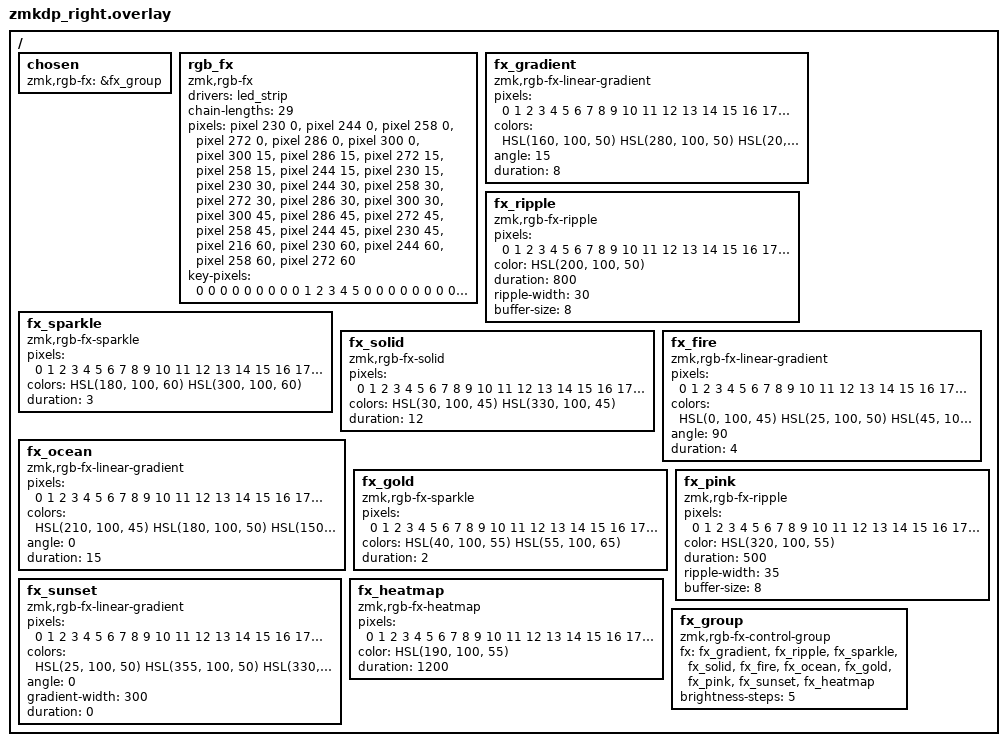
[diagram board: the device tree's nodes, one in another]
/*
 * RGB FX - right half (zmkdp, 29 LEDs).
 *
 * Wiring confirmed by annotated PCB photo (2026-10): the chain starts
 * at the top-INNER LED next to the MCU (photo LED1) and snakes across
 * the board, alternating direction every row; the standalone corner
 * light at the inner bottom is LED #25 (pixel 24), mid-chain, NOT the
 * chain start:
 *
 *     (keyboard view, seam on the LEFT, outer edge on the RIGHT)
 *         0  1  2  3  4  5
 *        11 10  9  8  7  6
 *        12 13 14 15 16 17
 *        23 22 21 20 19 18
 *        24 25 26 27 28      <- 24 = inner-bottom corner light
 *
 * Rows 1-4 have LEDs under the 6 outer columns (the innermost 7th key
 * column has none); the bottom row only under the inner 4 columns plus
 * the corner light. Canvas: x 216 (inner seam) .. 300 (outer), where
 * x = 300 - x_left. The left half (config/zmkdp_left.overlay) is the
 * axis-mirror of this mapping.
 *
 * key-pixels: 18 entries per row (7 left + 7 right + 4 third). Left and
 * third keys are remote here -> point to pixel 0 (inner top) so ripples
 * enter from the seam. Right keys map to their nearest LED; the
 * innermost 7th column has no LED in rows 1-4 and aliases to its row's
 * inner LED.
 */

#include <rgb_fx.dtsi>
#include <dt-bindings/zmk/rgb_fx.h>

/ {
    chosen {
        zmk,rgb-fx = &fx_group;
    };

    rgb_fx: rgb_fx {
        compatible = "zmk,rgb-fx";
        drivers = <&led_strip>;
        chain-lengths = <29>;
        pixels
            = <&pixel 230 0>,  /*  0 = top row, inner seam (chain start, MCU side) */
              <&pixel 244 0>,  /*  1 */
              <&pixel 258 0>,  /*  2 */
              <&pixel 272 0>,  /*  3 */
              <&pixel 286 0>,  /*  4 */
              <&pixel 300 0>,  /*  5 = top row, outer */
              <&pixel 300 15>, /*  6 = row 2, outer */
              <&pixel 286 15>, /*  7 */
              <&pixel 272 15>, /*  8 */
              <&pixel 258 15>, /*  9 */
              <&pixel 244 15>, /* 10 */
              <&pixel 230 15>, /* 11 = row 2, inner seam */
              <&pixel 230 30>, /* 12 = row 3, inner seam */
              <&pixel 244 30>, /* 13 */
              <&pixel 258 30>, /* 14 */
              <&pixel 272 30>, /* 15 */
              <&pixel 286 30>, /* 16 */
              <&pixel 300 30>, /* 17 = row 3, outer */
              <&pixel 300 45>, /* 18 = row 4, outer */
              <&pixel 286 45>, /* 19 */
              <&pixel 272 45>, /* 20 */
              <&pixel 258 45>, /* 21 */
              <&pixel 244 45>, /* 22 */
              <&pixel 230 45>, /* 23 = row 4, inner seam */
              <&pixel 216 60>, /* 24 = inner-bottom corner light */
              <&pixel 230 60>, /* 25 = bottom row, inner */
              <&pixel 244 60>, /* 26 */
              <&pixel 258 60>, /* 27 */
              <&pixel 272 60>; /* 28 = bottom row, outer */
        key-pixels
            = < 0  0  0  0  0  0  0   0  0  1  2  3  4  5   0 0 0 0
                0  0  0  0  0  0  0  11 11 10  9  8  7  6   0 0 0 0
                0  0  0  0  0  0  0  12 12 13 14 15 16 17   0 0 0 0
                0  0  0  0  0  0  0  23 23 22 21 20 19 18   0 0 0 0
                0  0  0  0  0  0  0  24 25 26 27 28 28 18   0 0 0 0>;
    };

    fx_gradient: fx_gradient {
        compatible = "zmk,rgb-fx-linear-gradient";
        pixels = <0 1 2 3 4 5 6 7 8 9 10 11 12 13 14 15 16 17 18 19 20 21 22 23 24 25 26 27 28>;
        colors = <HSL(160, 100, 50) HSL(280, 100, 50) HSL(20, 100, 50)>;
        angle = <15>;
        duration = <8>;
    };

    fx_ripple: fx_ripple {
        compatible = "zmk,rgb-fx-ripple";
        pixels = <0 1 2 3 4 5 6 7 8 9 10 11 12 13 14 15 16 17 18 19 20 21 22 23 24 25 26 27 28>;
        color = <HSL(200, 100, 50)>;
        duration = <800>;
        ripple-width = <30>;
        buffer-size = <8>;
    };

    fx_sparkle: fx_sparkle {
        compatible = "zmk,rgb-fx-sparkle";
        pixels = <0 1 2 3 4 5 6 7 8 9 10 11 12 13 14 15 16 17 18 19 20 21 22 23 24 25 26 27 28>;
        colors = <HSL(180, 100, 60) HSL(300, 100, 60)>;
        duration = <3>;
    };

    fx_solid: fx_solid {
        compatible = "zmk,rgb-fx-solid";
        pixels = <0 1 2 3 4 5 6 7 8 9 10 11 12 13 14 15 16 17 18 19 20 21 22 23 24 25 26 27 28>;
        colors = <HSL(30, 100, 45) HSL(330, 100, 45)>;
        duration = <12>;
    };

    fx_fire: fx_fire {
        compatible = "zmk,rgb-fx-linear-gradient";
        pixels = <0 1 2 3 4 5 6 7 8 9 10 11 12 13 14 15 16 17 18 19 20 21 22 23 24 25 26 27 28>;
        colors = <HSL(0, 100, 45) HSL(25, 100, 50) HSL(45, 100, 55)>;
        angle = <90>;
        duration = <4>;
    };

    fx_ocean: fx_ocean {
        compatible = "zmk,rgb-fx-linear-gradient";
        pixels = <0 1 2 3 4 5 6 7 8 9 10 11 12 13 14 15 16 17 18 19 20 21 22 23 24 25 26 27 28>;
        colors = <HSL(210, 100, 45) HSL(180, 100, 50) HSL(150, 90, 45)>;
        angle = <0>;
        duration = <15>;
    };

    fx_gold: fx_gold {
        compatible = "zmk,rgb-fx-sparkle";
        pixels = <0 1 2 3 4 5 6 7 8 9 10 11 12 13 14 15 16 17 18 19 20 21 22 23 24 25 26 27 28>;
        colors = <HSL(40, 100, 55) HSL(55, 100, 65)>;
        duration = <2>;
    };

    fx_pink: fx_pink {
        compatible = "zmk,rgb-fx-ripple";
        pixels = <0 1 2 3 4 5 6 7 8 9 10 11 12 13 14 15 16 17 18 19 20 21 22 23 24 25 26 27 28>;
        color = <HSL(320, 100, 55)>;
        duration = <500>;
        ripple-width = <35>;
        buffer-size = <8>;
    };

    fx_sunset: fx_sunset {
        compatible = "zmk,rgb-fx-linear-gradient";
        pixels = <0 1 2 3 4 5 6 7 8 9 10 11 12 13 14 15 16 17 18 19 20 21 22 23 24 25 26 27 28>;
        colors = <HSL(25, 100, 50) HSL(355, 100, 50) HSL(330, 100, 50)
                  HSL(285, 100, 50) HSL(235, 100, 50)>;
        angle = <0>;
        gradient-width = <300>;
        duration = <0>;
    };

    fx_heatmap: fx_heatmap {
        compatible = "zmk,rgb-fx-heatmap";
        pixels = <0 1 2 3 4 5 6 7 8 9 10 11 12 13 14 15 16 17 18 19 20 21 22 23 24 25 26 27 28>;
        color = <HSL(190, 100, 55)>;
        duration = <1200>;
    };

    fx_group: fx_group {
        compatible = "zmk,rgb-fx-control-group";
        fx = <&fx_gradient &fx_ripple &fx_sparkle &fx_solid
              &fx_fire &fx_ocean &fx_gold &fx_pink &fx_sunset &fx_heatmap>;
        brightness-steps = <5>;
    };
};
